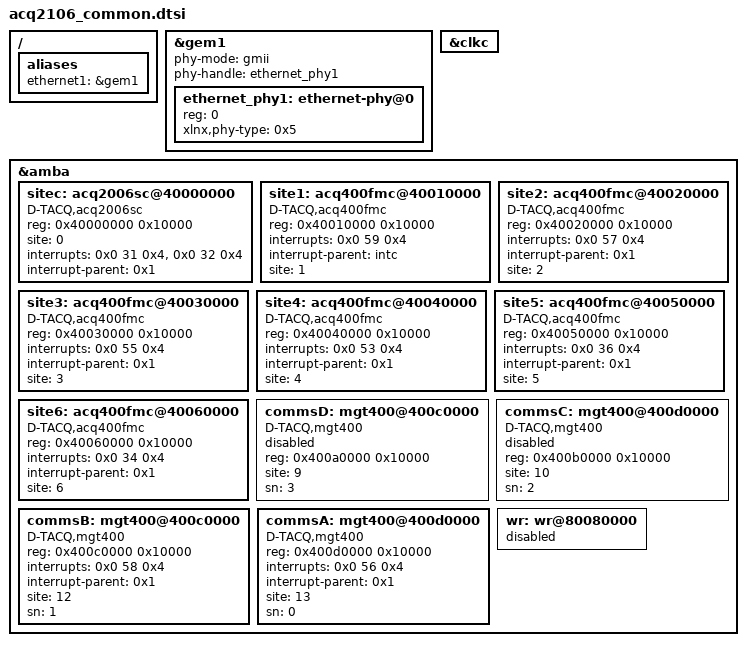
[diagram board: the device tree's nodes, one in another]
// SPDX-License-Identifier: GPL-2.0+
/*
 *   Copyright (C) 2013-2019 D-TACQ Solutions Ltd - http://www.d-tacq.com/
 *
 * This program is free software; you can redistribute it and/or modify
 * it under the terms of the GNU General Public License version 2 as
 * published by the Free Software Foundation.
 */
/dts-v1/;


#include "acq400_common.dtsi"
#include "acq2106_i2c.dtsi"

/ {
	 aliases {
		    ethernet1 = &gem1;
	 };	 
 };
 
/* gem1 connects to SFP3 1000-baseX , available AFTER FPGA boot, enable with overlay */
&gem1 {
	 phy-mode = "gmii";
	 phy-handle = <&ethernet_phy1>;
 
	 ethernet_phy1: ethernet-phy@0 {
		 reg = <0>;
		 xlnx,phy-type = <0x5>;
		 /* device_type = "ethernet-phy"; */
	 };
 };

&clkc {
	/* has no effect */
	clock-names = "gem1_emio_clk";
}; 

&amba {
	sitec: acq2006sc@40000000 {
		reg = <0x40000000 0x10000>;
		compatible = "D-TACQ,acq2006sc";
		site = <0>;
		interrupts = <0x0 31 0x4>, <0x0 32 0x4>;
		interrupt-parent = <0x1>;
	};
	site1: acq400fmc@40010000 {
		compatible = "D-TACQ,acq400fmc";
		reg = <0x40010000 0x10000>;
		interrupts = <0x0 59 0x4>; 
		interrupt-parent = <&intc>;
		site = <1>;
	};
	site2: acq400fmc@40020000 {
		compatible = "D-TACQ,acq400fmc";
		reg = <0x40020000 0x10000>;
		interrupts = <0x0 57 0x4>;
		interrupt-parent = <0x1>;
		site = <2>;
	};
	site3: acq400fmc@40030000 {
		compatible = "D-TACQ,acq400fmc";
		reg = <0x40030000 0x10000>;
		interrupts = <0x0 55 0x4>;
		interrupt-parent = <0x1>;
		site = <3>;
	};
	site4: acq400fmc@40040000 {
		compatible = "D-TACQ,acq400fmc";
		reg = <0x40040000 0x10000>;
		interrupts = <0x0 53 0x4>; 
		interrupt-parent = <0x1>;
		site = <4>;
	};
	site5: acq400fmc@40050000 {
		compatible = "D-TACQ,acq400fmc";
		reg = <0x40050000 0x10000>;
		interrupts = <0x0 36 0x4>;
		interrupt-parent = <0x1>;
		site = <5>;
	};
	site6: acq400fmc@40060000 {
		compatible = "D-TACQ,acq400fmc";
		reg = <0x40060000 0x10000>;
		interrupts = <0x0 34 0x4>;
		interrupt-parent = <0x1>;
		site = <6>;
	};
	commsD: mgt400@400c0000 {
		status = "disabled";
		compatible = "D-TACQ,mgt400";
		reg = <0x400a0000 0x10000>;
		/* interrupts = <0x0 58 0x4>; */
		/* interrupt-parent = <0x1>;  */
		site = <9>;
		sn = <3>;
	};
	commsC: mgt400@400d0000 {
		status = "disabled";
		compatible = "D-TACQ,mgt400";
		reg = <0x400b0000 0x10000>;
		/* interrupts = <0x0 56 0x4>; */
		/* interrupt-parent = <0x1>;  */
		site = <10>;
		sn = <2>;
	};	
	commsB: mgt400@400c0000 {
		status = "okay";
		compatible = "D-TACQ,mgt400";
		reg = <0x400c0000 0x10000>;			
		interrupts = <0x0 58 0x4>;
		interrupt-parent = <0x1>;
		site = <12>;
		sn = <1>;
	};
	commsA: mgt400@400d0000 {
		status = "okay";
		compatible = "D-TACQ,mgt400";
		reg = <0x400d0000 0x10000>;						
		interrupts = <0x0 56 0x4>;
		interrupt-parent = <0x1>;
		site = <13>;
		sn = <0>;
	};	
	/* dsp1, dsp2 : see acq400_common.dtsi */
	wr: wr@80080000 {
		status = "disabled";   /* @@todo : how does WR figure this? */
	};
	/* axiA, axiB : see acq400_common.dtsi */
};
